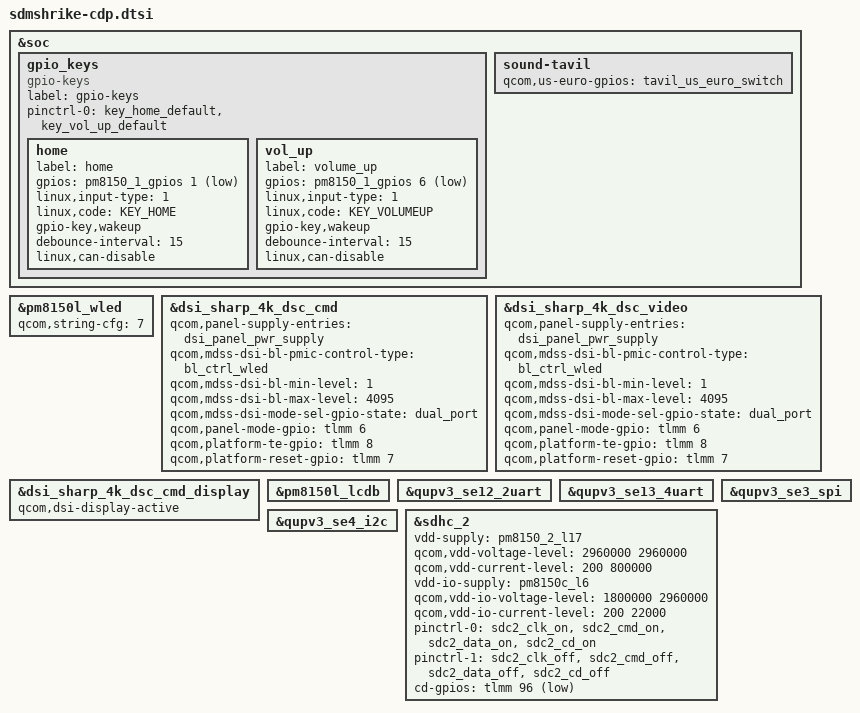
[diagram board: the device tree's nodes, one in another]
/* Copyright (c) 2018-2019, The Linux Foundation. All rights reserved.
 *
 * This program is free software; you can redistribute it and/or modify
 * it under the terms of the GNU General Public License version 2 and
 * only version 2 as published by the Free Software Foundation.
 *
 * This program is distributed in the hope that it will be useful,
 * but WITHOUT ANY WARRANTY; without even the implied warranty of
 * MERCHANTABILITY or FITNESS FOR A PARTICULAR PURPOSE.  See the
 * GNU General Public License for more details.
 */

#include <dt-bindings/gpio/gpio.h>
#include <dt-bindings/input/input.h>
#include "sdmshrike-sde-display.dtsi"

#include "sdmshrike-pmic-overlay.dtsi"
#include "sdmshrike-audio-overlay.dtsi"
#include "sdmshrike-thermal-overlay.dtsi"

&soc {
	gpio_keys {
		compatible = "gpio-keys";
		label = "gpio-keys";

		pinctrl-names = "default";
		pinctrl-0 = <&key_home_default
			     &key_vol_up_default>;

		home {
			label = "home";
			gpios = <&pm8150_1_gpios 1 GPIO_ACTIVE_LOW>;
			linux,input-type = <1>;
			linux,code = <KEY_HOME>;
			gpio-key,wakeup;
			debounce-interval = <15>;
			linux,can-disable;
		};

		vol_up {
			label = "volume_up";
			gpios = <&pm8150_1_gpios 6 GPIO_ACTIVE_LOW>;
			linux,input-type = <1>;
			linux,code = <KEY_VOLUMEUP>;
			gpio-key,wakeup;
			debounce-interval = <15>;
			linux,can-disable;
		};
	};

	sound-tavil {
		qcom,us-euro-gpios = <&tavil_us_euro_switch>;
	};
};

&pm8150l_wled {
	qcom,string-cfg= <7>;
	status = "ok";
};

&dsi_sharp_4k_dsc_cmd {
	qcom,panel-supply-entries = <&dsi_panel_pwr_supply>;
	qcom,mdss-dsi-bl-pmic-control-type = "bl_ctrl_wled";
	qcom,mdss-dsi-bl-min-level = <1>;
	qcom,mdss-dsi-bl-max-level = <4095>;
	qcom,mdss-dsi-mode-sel-gpio-state = "dual_port";
	qcom,panel-mode-gpio = <&tlmm 6 0>;
	qcom,platform-te-gpio = <&tlmm 8 0>;
	qcom,platform-reset-gpio = <&tlmm 7 0>;
};

&dsi_sharp_4k_dsc_video {
	qcom,panel-supply-entries = <&dsi_panel_pwr_supply>;
	qcom,mdss-dsi-bl-pmic-control-type = "bl_ctrl_wled";
	qcom,mdss-dsi-bl-min-level = <1>;
	qcom,mdss-dsi-bl-max-level = <4095>;
	qcom,mdss-dsi-mode-sel-gpio-state = "dual_port";
	qcom,panel-mode-gpio = <&tlmm 6 0>;
	qcom,platform-te-gpio = <&tlmm 8 0>;
	qcom,platform-reset-gpio = <&tlmm 7 0>;
};

&dsi_sharp_4k_dsc_cmd_display {
	qcom,dsi-display-active;
};

&pm8150l_lcdb {
	status = "ok";
};

&qupv3_se12_2uart {
	status = "ok";
};

&qupv3_se13_4uart {
	status = "ok";
};

&qupv3_se3_spi {
	status = "ok";
};

&qupv3_se4_i2c {
	status = "ok";
};

&sdhc_2 {
	vdd-supply = <&pm8150_2_l17>;
	qcom,vdd-voltage-level = <2960000 2960000>;
	qcom,vdd-current-level = <200 800000>;

	vdd-io-supply = <&pm8150c_l6>;
	qcom,vdd-io-voltage-level = <1800000 2960000>;
	qcom,vdd-io-current-level = <200 22000>;

	pinctrl-names = "active", "sleep";
	pinctrl-0 = <&sdc2_clk_on  &sdc2_cmd_on &sdc2_data_on &sdc2_cd_on>;
	pinctrl-1 = <&sdc2_clk_off &sdc2_cmd_off &sdc2_data_off &sdc2_cd_off>;

	cd-gpios = <&tlmm 96 1>;

	status = "ok";
};
